AUTOSAR XML (schema 4-2-2)
# Copyright 2015 Mentor Graphics Corporation
# All Rights Reserved
# THIS WORK CONTAINS TRADE SECRET
# AND PROPRIETARY INFORMATION WHICH IS THE
# PROPERTY OF MENTOR GRAPHICS
# CORPORATION OR ITS LICENSORS AND IS
# SUBJECT TO LICENSE TERMS.
package /AUTOSAR/Services/NvM
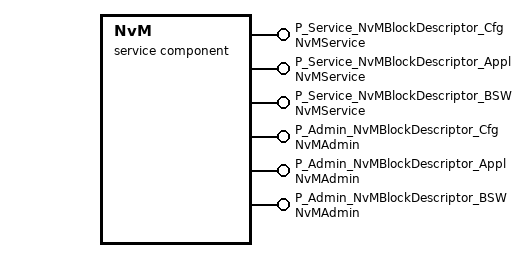
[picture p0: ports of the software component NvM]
  service sw component type NvM
    6 x provide port:
      P_Service_NvMBlockDescriptor_Cfg: provided-interface=NvMService
      P_Service_NvMBlockDescriptor_Appl: provided-interface=NvMService
      P_Service_NvMBlockDescriptor_BSW: provided-interface=NvMService
      P_Admin_NvMBlockDescriptor_Cfg: provided-interface=NvMAdmin
      P_Admin_NvMBlockDescriptor_Appl: provided-interface=NvMAdmin
      P_Admin_NvMBlockDescriptor_BSW: provided-interface=NvMAdmin
    behavior IB_NVM
      30 x operation invoked event:
        EV_GetErrorStatus_Block1: start-on-event=GetErrorStatus, operation=P_Service_NvMBlockDescriptor_Cfg.GetErrorStatus
        EV_SetDataIndex_Block1: start-on-event=SetDataIndex, operation=P_Service_NvMBlockDescriptor_Cfg.SetDataIndex
        EV_SetRamBlockStatus_Block1: start-on-event=SetRamBlockStatus, operation=P_Service_NvMBlockDescriptor_Cfg.SetRamBlockStatus
        EV_GetDataIndex_Block1: start-on-event=GetDataIndex, operation=P_Service_NvMBlockDescriptor_Cfg.GetDataIndex
        EV_ReadBlock_Block1: start-on-event=ReadBlock, operation=P_Service_NvMBlockDescriptor_Cfg.ReadBlock
        EV_WriteBlock_Block1: start-on-event=WriteBlock, operation=P_Service_NvMBlockDescriptor_Cfg.WriteBlock
        EV_RestoreBlockDefaults_Block1: start-on-event=RestoreBlockDefaults, operation=P_Service_NvMBlockDescriptor_Cfg.RestoreBlockDefaults
        EV_EraseNvBlock_Block1: start-on-event=EraseNvBlock, operation=P_Service_NvMBlockDescriptor_Cfg.EraseBlock
        EV_InvalidateNvBlock_Block1: start-on-event=InvalidateNvBlock, operation=P_Service_NvMBlockDescriptor_Cfg.InvalidateNvBlock
        EV_SetBlockProtection_Block1: start-on-event=SetBlockProtection, operation=P_Admin_NvMBlockDescriptor_Cfg.SetBlockProtection
        EV_GetErrorStatus_Block2: start-on-event=GetErrorStatus, operation=P_Service_NvMBlockDescriptor_Appl.GetErrorStatus
        EV_SetDataIndex_Block2: start-on-event=SetDataIndex, operation=P_Service_NvMBlockDescriptor_Appl.SetDataIndex
        EV_SetRamBlockStatus_Block2: start-on-event=SetRamBlockStatus, operation=P_Service_NvMBlockDescriptor_Appl.SetRamBlockStatus
        EV_GetDataIndex_Block2: start-on-event=GetDataIndex, operation=P_Service_NvMBlockDescriptor_Appl.GetDataIndex
        EV_ReadBlock_Block2: start-on-event=ReadBlock, operation=P_Service_NvMBlockDescriptor_Appl.ReadBlock
        EV_WriteBlock_Block2: start-on-event=WriteBlock, operation=P_Service_NvMBlockDescriptor_Appl.WriteBlock
        EV_RestoreBlockDefaults_Block2: start-on-event=RestoreBlockDefaults, operation=P_Service_NvMBlockDescriptor_Appl.RestoreBlockDefaults
        EV_EraseNvBlock_Block2: start-on-event=EraseNvBlock, operation=P_Service_NvMBlockDescriptor_Appl.EraseBlock
        EV_InvalidateNvBlock_Block2: start-on-event=InvalidateNvBlock, operation=P_Service_NvMBlockDescriptor_Appl.InvalidateNvBlock
        EV_SetBlockProtection_Block2: start-on-event=SetBlockProtection, operation=P_Admin_NvMBlockDescriptor_Appl.SetBlockProtection
        EV_GetErrorStatus_Block3: start-on-event=GetErrorStatus, operation=P_Service_NvMBlockDescriptor_BSW.GetErrorStatus
        EV_SetDataIndex_Block3: start-on-event=SetDataIndex, operation=P_Service_NvMBlockDescriptor_BSW.SetDataIndex
        EV_SetRamBlockStatus_Block3: start-on-event=SetRamBlockStatus, operation=P_Service_NvMBlockDescriptor_BSW.SetRamBlockStatus
        EV_GetDataIndex_Block3: start-on-event=GetDataIndex, operation=P_Service_NvMBlockDescriptor_BSW.GetDataIndex
        EV_ReadBlock_Block3: start-on-event=ReadBlock, operation=P_Service_NvMBlockDescriptor_BSW.ReadBlock
        EV_WriteBlock_Block3: start-on-event=WriteBlock, operation=P_Service_NvMBlockDescriptor_BSW.WriteBlock
        EV_RestoreBlockDefaults_Block3: start-on-event=RestoreBlockDefaults, operation=P_Service_NvMBlockDescriptor_BSW.RestoreBlockDefaults
        EV_EraseNvBlock_Block3: start-on-event=EraseNvBlock, operation=P_Service_NvMBlockDescriptor_BSW.EraseBlock
        EV_InvalidateNvBlock_Block3: start-on-event=InvalidateNvBlock, operation=P_Service_NvMBlockDescriptor_BSW.InvalidateNvBlock
        EV_SetBlockProtection_Block3: start-on-event=SetBlockProtection, operation=P_Admin_NvMBlockDescriptor_BSW.SetBlockProtection
      port-api-options:
        {indirect-api=true, port-defined-argument-value{value=1, value-type=NvM_BlockIdType}, port=P_Service_NvMBlockDescriptor_Cfg}
        {indirect-api=true, port-defined-argument-value{value=2, value-type=NvM_BlockIdType}, port=P_Service_NvMBlockDescriptor_Appl}
        {indirect-api=true, port-defined-argument-value{value=3, value-type=NvM_BlockIdType}, port=P_Service_NvMBlockDescriptor_BSW}
        {indirect-api=true, port-defined-argument-value{value=1, value-type=NvM_BlockIdType}, port=P_Admin_NvMBlockDescriptor_Cfg}
        {indirect-api=true, port-defined-argument-value{value=2, value-type=NvM_BlockIdType}, port=P_Admin_NvMBlockDescriptor_Appl}
        {indirect-api=true, port-defined-argument-value{value=3, value-type=NvM_BlockIdType}, port=P_Admin_NvMBlockDescriptor_BSW}
      11 x runnable, all with can-be-invoked-concurrently=true:
        ReadBlock: symbol=NvM_ReadBlock
        GetErrorStatus: symbol=NvM_GetErrorStatus
        SetDataIndex: symbol=NvM_SetDataIndex
        GetDataIndex: symbol=NvM_GetDataIndex
        SetRamBlockStatus: symbol=NvM_SetRamBlockStatus
        RestoreBlockDefaults: symbol=NvM_RestoreBlockDefaults
        EraseNvBlock: symbol=NvM_EraseNvBlock
        InvalidateNvBlock: symbol=NvM_InvalidateNvBlock
        SetBlockProtection: symbol=NvM_SetBlockProtection
        WriteBlock: symbol=NvM_WriteBlock
        NvM_MainFunction
  swc implementation IMPL_NvM: programming-language=C, sw-version=8.2.0, swc-bsw-mapping=SwcBswMapping_NvM, used-code-generator=vstar_nvm_scg.exe, vendor-id=31, behavior=IB_NVM
    resource consumption RC_NvM
      memory section CODE: alignment=UNSPECIFIED, sw-addrmethod=CODE
